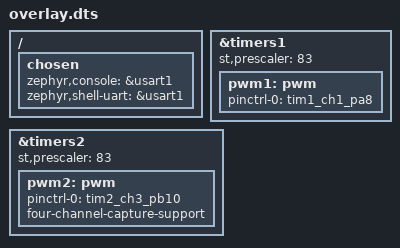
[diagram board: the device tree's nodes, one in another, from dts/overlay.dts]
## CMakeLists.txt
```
cmake_minimum_required(VERSION 3.20.0)

# ─── Point to our overlay before Zephyr loads ─────────────────────────────────
set(DTC_OVERLAY_FILE ${CMAKE_CURRENT_SOURCE_DIR}/dts/overlay.dts)

# ─── Zephyr package ───────────────────────────────────────────────────────────
find_package(Zephyr REQUIRED HINTS $ENV{ZEPHYR_BASE})
project(testbench)

# ─── Main executable ──────────────────────────────────────────────────────────
target_sources(app PRIVATE src/main.c)

# ─── Source library ───────────────────────────────────────────────────────────
target_sources(app PRIVATE
    src/serial_handler.c
    src/command_parser.c
    src/executor.c
    src/validator.c
    src/handlers/pwm_out.c
    src/handlers/pwm_capture.c
)

# ─── Include paths ────────────────────────────────────────────────────────────
target_include_directories(app PRIVATE
    src
    src/handlers
)
```

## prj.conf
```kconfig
# ─── UART ─────────────────────────────────────────────────────────────────────
CONFIG_SERIAL=y
CONFIG_UART_INTERRUPT_DRIVEN=y

# ─── PWM ──────────────────────────────────────────────────────────────────────
CONFIG_PWM=y
CONFIG_PWM_CAPTURE=y

# ─── Logging / debug ──────────────────────────────────────────────────────────
CONFIG_LOG=y
CONFIG_PRINTK=y
CONFIG_UART_CONSOLE=y

# ─── Main thread stack ────────────────────────────────────────────────────────
CONFIG_MAIN_STACK_SIZE=2048

# ─── Heap (needed for any dynamic allocation) ─────────────────────────────────
CONFIG_HEAP_MEM_POOL_SIZE=1024
```

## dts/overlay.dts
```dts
/*
 * Testbench overlay — STM32F401CC Black Pill
 *
 * PA8  — TIM1 CH1 — PWM output
 * PB10 — TIM2 CH3 — PWM capture
 * PA9  — USART1 TX (already in board file)
 * PA10 — USART1 RX (already in board file)
 */

#include <st/f4/stm32f401ccfx-pinctrl.dtsi>

/ {
    chosen {
        zephyr,console    = &usart1;
        zephyr,shell-uart = &usart1;
    };
};

/* ─── TIM1 — PWM output on PA8 (CH1) ────────────────────────────────────── */
&timers1 {
    status = "okay";
    st,prescaler = <83>;

    pwm1: pwm {
        status = "okay";
        pinctrl-0 = <&tim1_ch1_pa8>;
        pinctrl-names = "default";
        #pwm-cells = <3>;
    };
};

/* ─── TIM2 — PWM capture on PB10 (CH3) ──────────────────────────────────── */
&timers2 {
    status = "okay";
    st,prescaler = <83>;

    pwm2: pwm {
        status = "okay";
        pinctrl-0 = <&tim2_ch3_pb10>;
        pinctrl-names = "default";
        #pwm-cells = <3>;

        /* PB10 is TIM2_CH3. Default STM32 slave-mode capture only
         * works on CH1/CH2, so capturing on CH3 needs four-channel
         * mode (counter reset by IRQ instead of slave controller). */
        four-channel-capture-support;
    };
};
```

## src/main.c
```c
#include <zephyr/kernel.h>

#include "serial_handler.h"
#include "command_parser.h"
#include "executor.h"

#define RESP_BUF_SIZE   64
static char resp[RESP_BUF_SIZE];

/* ─────────────────────────────────────────────────────────────
 * main — all blocking work happens here in main loop
 * interrupt only sets a flag in serial_handler
 *
 * this is critical — pwm_capture_cycles blocks for timeout_ms
 * it CANNOT run inside an interrupt callback
 * ───────────────────────────────────────────────────────────── */
int main(void)
{
    /* static: parsed_cmd_t is ~2.5 KB — too large for the main stack
     * (CONFIG_MAIN_STACK_SIZE=2048). Single-threaded loop, so one
     * shared instance is safe and keeps it off the stack. */
    static parsed_cmd_t cmd;
    parse_result_t  pres;
    const char     *frame;

    /* init UART interrupt */
    serial_handler_init();

    while (1) {

        /* wait for a complete frame — sleep 1ms between checks */
        if (!serial_frame_ready()) {
            k_msleep(1);
            continue;
        }

        /* get the frame — clears the ready flag */
        frame = serial_get_frame();

        /* parse */
        pres = command_parse(frame, &cmd);
        if (pres != PARSE_OK) {
            serial_send(parse_result_str(pres));
            continue;
        }

        /* execute — blocking operations happen here safely */
        executor_run(&cmd, resp, RESP_BUF_SIZE);

        /* send response */
        serial_send(resp);
    }

    return 0;
}
```

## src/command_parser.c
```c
#include "command_parser.h"
#include <string.h>
#include <stdlib.h>

/* working buffer — we copy the frame here before splitting
 * because strtok destroys the string it works on            */
static char buf[256];

/* ─────────────────────────────────────────────────────────────
 * convert action string to enum
 * input : "PWM" / "GPIO" / "UART" / "SPI" / "ADC"
 * output: matching action_t value, or ACTION_UNKNOWN
 * ───────────────────────────────────────────────────────────── */
static action_t parse_action(const char *str)
{
    if (strcmp(str, "PWM")  == 0) return ACTION_PWM;
    if (strcmp(str, "GPIO") == 0) return ACTION_GPIO;
    if (strcmp(str, "UART") == 0) return ACTION_UART;
    if (strcmp(str, "SPI")  == 0) return ACTION_SPI;
    if (strcmp(str, "ADC")  == 0) return ACTION_ADC;

    return ACTION_UNKNOWN;
}

/* ─────────────────────────────────────────────────────────────
 * parse one operation from a colon-separated token
 *
 * example input : "PWM:PA8:50:90"
 * example output: op->action   = ACTION_PWM
 *                 op->pin      = "PA8"
 *                 op->num_params  = {50, 90}
 *                 op->num_param_count = 2
 *
 * rule: if param starts with digit  → goes to num_params
 *       if param starts with letter → goes to str_params
 * ───────────────────────────────────────────────────────────── */
static parse_result_t parse_operation(char *token, operation_t *op)
{
    char *field;
    char *save;     /* own strtok_r context — must not share with callers */

    /* zero the operation before filling it */
    memset(op, 0, sizeof(operation_t));

    /* ── step 1: action ── */
    field = strtok_r(token, ":", &save);
    if (!field) return PARSE_ERR_BAD_FRAME;

    op->action = parse_action(field);
    if (op->action == ACTION_UNKNOWN) return PARSE_ERR_BAD_ACTION;

    /* ── step 2: pin ── */
    field = strtok_r(NULL, ":", &save);
    if (!field) return PARSE_ERR_BAD_FRAME;

    strncpy(op->pin, field, MAX_PIN_LEN - 1);

    /* ── step 3: remaining params ── */
    field = strtok_r(NULL, ":", &save);

    while (field != NULL) {

        if (field[0] >= '0' && field[0] <= '9') {
            /* numeric param — e.g. "50", "90", "1" */
            op->num_params[op->num_param_count] = (uint32_t)atoi(field);
            op->num_param_count++;

        } else {
            /* string param — e.g. "forward", "0x55" */
            strncpy(op->str_params[op->str_param_count],
                    field,
                    MAX_STR_PARAM_LEN - 1);
            op->str_param_count++;
        }

        /* get next param */
        field = strtok_r(NULL, ":", &save);
    }

    return PARSE_OK;
}

/* ─────────────────────────────────────────────────────────────
 * parse a block of comma-separated operations
 *
 * example input : "GPIO:PB10:1,GPIO:PB9:1"
 * example output: ops[0] = {GPIO, PB10, num={1}}
 *                 ops[1] = {GPIO, PB9,  num={1}}
 *                 count  = 2
 * ───────────────────────────────────────────────────────────── */
static parse_result_t parse_block(char *block, operation_t *ops, uint8_t *count)
{
    parse_result_t res;
    char *token;
    char *save;     /* own strtok_r context — independent of parse_operation */

    *count = 0;

    /* split block by comma — each piece is one operation */
    token = strtok_r(block, ",", &save);

    while (token != NULL) {

        /* safety check — don't overflow ops array */
        if (*count >= MAX_OPS) return PARSE_ERR_TOO_MANY_OPS;

        /* parse this operation into the next slot */
        res = parse_operation(token, &ops[*count]);
        if (res != PARSE_OK) return res;

        (*count)++;

        /* move to next operation */
        token = strtok_r(NULL, ",", &save);
    }

    return PARSE_OK;
}

/* ─────────────────────────────────────────────────────────────
 * main parse function — only function called from outside
 *
 * full frame format:
 * "SET:<op>,<op>|ASSERT:<op>,<op>|TIMEOUT:<ms>"
 *
 * examples:
 * "SET:PWM:PA8:50:90|ASSERT:PWM:PB10:50:90|TIMEOUT:1000"
 * "SET:GPIO:PB10:1,GPIO:PB9:1|ASSERT:GPIO:PB11:1|TIMEOUT:500"
 * ───────────────────────────────────────────────────────────── */
parse_result_t command_parse(const char *frame, parsed_cmd_t *out)
{
    char *section;
    char *save;     /* own strtok_r context for the top-level '|' split */

    /* zero the output struct before filling it */
    memset(out, 0, sizeof(parsed_cmd_t));

    /* reject empty frame */
    if (!frame || frame[0] == '\0') return PARSE_ERR_EMPTY;

    /* copy frame into working buffer */
    strncpy(buf, frame, sizeof(buf) - 1);
    buf[sizeof(buf) - 1] = '\0';

    /* strip trailing newline */
    size_t len = strlen(buf);
    if (len > 0 && (buf[len-1] == '\n' || buf[len-1] == '\r')) {
        buf[len-1] = '\0';
    }

    /* split full frame by '|' to get sections
     * section 0 → "SET:..."
     * section 1 → "ASSERT:..."
     * section 2 → "TIMEOUT:..."         */
    section = strtok_r(buf, "|", &save);

    while (section != NULL) {

        if (strncmp(section, "SET:", 4) == 0) {
            /* skip past "SET:" and parse the operations block */
            parse_block(section + 4, out->set_ops, &out->set_count);

        } else if (strncmp(section, "ASSERT:", 7) == 0) {
            /* skip past "ASSERT:" and parse the operations block */
            parse_block(section + 7, out->assert_ops, &out->assert_count);

        } else if (strncmp(section, "TIMEOUT:", 8) == 0) {
            /* skip past "TIMEOUT:" and read the number */
            out->timeout_ms = (uint32_t)atoi(section + 8);

        } else {
            return PARSE_ERR_BAD_FRAME;
        }

        /* move to next section */
        section = strtok_r(NULL, "|", &save);
    }

    return PARSE_OK;
}

/* ─────────────────────────────────────────────────────────────
 * convert result code to string for UART response
 * ───────────────────────────────────────────────────────────── */
const char *parse_result_str(parse_result_t result)
{
    switch (result) {
        case PARSE_OK:               return "OK";
        case PARSE_ERR_EMPTY:        return "FAIL:EMPTY_FRAME";
        case PARSE_ERR_BAD_ACTION:   return "FAIL:BAD_ACTION";
        case PARSE_ERR_BAD_FRAME:    return "FAIL:BAD_FRAME";
        case PARSE_ERR_OUT_OF_RANGE: return "FAIL:OUT_OF_RANGE";
        case PARSE_ERR_TOO_MANY_OPS: return "FAIL:TOO_MANY_OPS";
        default:                     return "FAIL:UNKNOWN";
    }
}
```

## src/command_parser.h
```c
#ifndef COMMAND_PARSER_H
#define COMMAND_PARSER_H

#include <stdint.h>

/* ─── Limits ─────────────────────────────────────────────────────────────── */
#define MAX_PIN_LEN         8       /* "PA8", "PB10" etc                     */
#define MAX_STR_PARAMS      4       /* max string params per operation        */
#define MAX_STR_PARAM_LEN   32      /* max length of each string param        */
#define MAX_NUM_PARAMS      4       /* max numeric params per operation       */
#define MAX_OPS             8       /* max operations per SET or ASSERT block */

/* ─── Action types ───────────────────────────────────────────────────────── */
typedef enum {
    ACTION_UNKNOWN = 0,
    ACTION_PWM,
    ACTION_GPIO,
    ACTION_UART,
    ACTION_SPI,
    ACTION_ADC,
} action_t;

/* ─── Single operation ───────────────────────────────────────────────────── */
/*
 * One action on one pin with its parameters.
 *
 * How each action uses params:
 *
 *   PWM:
 *     num_params[0] = frequency (Hz)
 *     num_params[1] = duty cycle (%)
 *
 *   GPIO:
 *     num_params[0] = level (0 or 1)
 *
 *   UART:
 *     str_params[0] = string to send e.g. "forward"
 *     str_params[1] = string to expect (assert side)
 *
 *   SPI:
 *     str_params[0] = hex bytes to send e.g. "0x55"
 *     str_params[1] = hex bytes to expect (assert side)
 *
 *   ADC:
 *     num_params[0] = expected voltage in mV
 */
typedef struct {
    action_t    action;
    char        pin[MAX_PIN_LEN];

    uint32_t    num_params[MAX_NUM_PARAMS];
    uint8_t     num_param_count;

    char        str_params[MAX_STR_PARAMS][MAX_STR_PARAM_LEN];
    uint8_t     str_param_count;
} operation_t;

/* ─── Full parsed command ────────────────────────────────────────────────── */
/*
 * Holds all SET operations and all ASSERT operations from one frame.
 *
 * Example frame:
 * "SET:GPIO:PB10:1,GPIO:PB9:1,PWM:PA8:50:90|ASSERT:PWM:PB10:50:90,GPIO:PB11:1|TIMEOUT:1000"
 *
 * Results in:
 *   set_ops[0]    = {ACTION_GPIO, "PB10", num_params={1}}
 *   set_ops[1]    = {ACTION_GPIO, "PB9",  num_params={1}}
 *   set_ops[2]    = {ACTION_PWM,  "PA8",  num_params={50, 90}}
 *   set_count     = 3
 *
 *   assert_ops[0] = {ACTION_PWM,  "PB10", num_params={50, 90}}
 *   assert_ops[1] = {ACTION_GPIO, "PB11", num_params={1}}
 *   assert_count  = 2
 *
 *   timeout_ms    = 1000
 */
typedef struct {
    operation_t set_ops[MAX_OPS];
    uint8_t     set_count;

    operation_t assert_ops[MAX_OPS];
    uint8_t     assert_count;

    uint32_t    timeout_ms;
} parsed_cmd_t;

/* ─── Return codes ───────────────────────────────────────────────────────── */
typedef enum {
    PARSE_OK = 0,
    PARSE_ERR_EMPTY,
    PARSE_ERR_BAD_ACTION,
    PARSE_ERR_BAD_FRAME,
    PARSE_ERR_OUT_OF_RANGE,
    PARSE_ERR_TOO_MANY_OPS,
} parse_result_t;

/* ─── API ────────────────────────────────────────────────────────────────── */

/**
 * @brief  Parse a raw UART frame into a command struct.
 *
 * @param  frame      Null-terminated string received over UART.
 *
 *   Format:
 *   "SET:<op1>,<op2>,...|ASSERT:<op1>,<op2>,...|TIMEOUT:<ms>"
 *
 *   Each operation: <ACTION>:<PIN>:<param1>:<param2>...
 *
 *   Examples:
 *   "SET:PWM:PA8:50:90|ASSERT:PWM:PB10:50:90|TIMEOUT:1000"
 *   "SET:GPIO:PB10:1,GPIO:PB9:1|ASSERT:GPIO:PB11:1,GPIO:PB12:0|TIMEOUT:500"
 *   "SET:UART:PA9:forward|ASSERT:GPIO:PB11:1,GPIO:PB12:0|TIMEOUT:500"
 *   "SET:GPIO:PB10:1,GPIO:PB9:1,PWM:PA8:50:90|ASSERT:PWM:PB10:50:90|TIMEOUT:1000"
 *
 * @param  out        Pointer to struct to fill. Cleared before parsing.
 * @return parse_result_t
 */
parse_result_t command_parse(const char *frame, parsed_cmd_t *out);

/**
 * @brief  Convert a parse result code to a human readable string.
 */
const char *parse_result_str(parse_result_t result);

#endif /* COMMAND_PARSER_H */
```

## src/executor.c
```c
#include "executor.h"
#include "validator.h"
#include "handlers/pwm_out.h"
#include "handlers/pwm_capture.h"

#include <zephyr/kernel.h>
#include <string.h>

/* settle time after SET before measuring — fixed 50ms */
#define SETTLE_MS   50

/* ─────────────────────────────────────────────────────────────
 * execute one SET operation
 * ───────────────────────────────────────────────────────────── */
static int execute_set(const operation_t *op, char *resp, uint16_t resp_len)
{
    switch (op->action) {

        case ACTION_PWM: {
            /* num_params[0] = frequency (Hz)
             * num_params[1] = duty cycle (%)  */
            pwm_out_result_t res = pwm_out_start(op->pin,
                                                  op->num_params[0],
                                                  op->num_params[1]);
            if (res != PWM_OUT_OK) {
                strncpy(resp, pwm_out_result_str(res), resp_len - 1);
                return -1;
            }
            return 0;
        }

        default:
            strncpy(resp, "FAIL:UNKNOWN_SET_ACTION", resp_len - 1);
            return -1;
    }
}

/* ─────────────────────────────────────────────────────────────
 * execute one ASSERT operation
 * ───────────────────────────────────────────────────────────── */
static int execute_assert(const operation_t *op,
                          uint32_t timeout_ms,
                          char *resp,
                          uint16_t resp_len)
{
    measured_t measured;
    validate_result_t vres;

    switch (op->action) {

        case ACTION_PWM: {
            /* measure PWM on the assert pin */
            pwm_cap_result_t res = pwm_capture_measure(op->pin,
                                                        timeout_ms,
                                                        &measured);
            /* capture failed — timeout or device error */
            if (res != PWM_CAP_OK) {
                strncpy(resp, pwm_cap_result_str(res), resp_len - 1);
                return -1;
            }

            /* validate measured vs expected */
            vres = validate(op, &measured);
            if (vres != VALIDATE_OK) {
                strncpy(resp, validate_result_str(vres), resp_len - 1);
                return -1;
            }

            return 0;
        }

        default:
            strncpy(resp, "FAIL:UNKNOWN_ASSERT_ACTION", resp_len - 1);
            return -1;
    }
}

/* ─────────────────────────────────────────────────────────────
 * main executor
 *
 * phase 1 — SET:    drive all set operations
 * phase 2 — WAIT:   fixed settle time (50ms)
 * phase 3 — ASSERT: measure and validate all assert operations
 *           uses timeout_ms from command as capture window
 * ───────────────────────────────────────────────────────────── */
void executor_run(const parsed_cmd_t *cmd, char *resp, uint16_t resp_len)
{
    memset(resp, 0, resp_len);

    /* ── phase 1: SET ── */
    for (uint8_t i = 0; i < cmd->set_count; i++) {
        if (execute_set(&cmd->set_ops[i], resp, resp_len) != 0) {
            return;
        }
    }

    /* ── phase 2: WAIT ──
     * fixed settle time — gives signal time to stabilise
     * separate from capture timeout                          */
    k_msleep(SETTLE_MS);

    /* ── phase 3: ASSERT ── */
    for (uint8_t i = 0; i < cmd->assert_count; i++) {
        if (execute_assert(&cmd->assert_ops[i],
                           cmd->timeout_ms,
                           resp,
                           resp_len) != 0) {
            return;
        }
    }

    strncpy(resp, "OK", resp_len - 1);
}
```

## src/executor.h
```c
#ifndef EXECUTOR_H
#define EXECUTOR_H

#include "command_parser.h"

/* ─── Return codes ───────────────────────────────────────────────────────── */
typedef enum {
    EXEC_OK = 0,
    EXEC_FAIL_SET,              /* something went wrong during SET phase      */
    EXEC_FAIL_ASSERT,           /* assertion failed — measured != expected    */
    EXEC_FAIL_UNKNOWN_ACTION,   /* action type not supported                  */
    EXEC_FAIL_CAPTURE,          /* capture/measurement failed                 */
} exec_result_t;

/* ─── API ────────────────────────────────────────────────────────────────── */

/**
 * @brief  Execute a fully parsed command.
 *
 *         Phase 1 — SET:    loop through set_ops, drive each one
 *         Phase 2 — WAIT:   wait timeout_ms for DUT to settle
 *         Phase 3 — ASSERT: loop through assert_ops, measure and validate each
 *
 * @param  cmd        Fully parsed command from command_parse()
 * @param  resp       Buffer to write the response string into
 * @param  resp_len   Size of response buffer
 */
void executor_run(const parsed_cmd_t *cmd, char *resp, uint16_t resp_len);

#endif /* EXECUTOR_H */
```

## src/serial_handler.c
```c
#include "serial_handler.h"

#include <zephyr/kernel.h>
#include <zephyr/drivers/uart.h>
#include <string.h>

static const struct device *uart = DEVICE_DT_GET(DT_CHOSEN(zephyr_console));

static char     rx_buf[SERIAL_BUF_SIZE];    /* accumulate bytes here        */
static char     frame_buf[SERIAL_BUF_SIZE]; /* complete frame stored here   */
static uint16_t rx_pos   = 0;
static bool     frame_ready = false;        /* set by ISR, cleared by main  */

/* ─────────────────────────────────────────────────────────────
 * UART interrupt — runs in interrupt context
 * ONLY accumulates bytes and sets a flag
 * does NOT call any blocking functions
 * ───────────────────────────────────────────────────────────── */
static void uart_cb(const struct device *dev, void *user_data)
{
    uint8_t byte;

    if (!uart_irq_update(dev) || !uart_irq_rx_ready(dev)) {
        return;
    }

    while (uart_fifo_read(dev, &byte, 1) == 1) {

        if (byte == '\r') continue;

        if (byte == '\n') {
            rx_buf[rx_pos] = '\0';

            /* only accept frame if we are not already processing one */
            if (rx_pos > 0 && !frame_ready) {
                memcpy(frame_buf, rx_buf, rx_pos + 1);
                frame_ready = true;
            }

            rx_pos = 0;
            return;
        }

        if (rx_pos < SERIAL_BUF_SIZE - 1) {
            rx_buf[rx_pos++] = byte;
        } else {
            rx_pos = 0;
        }
    }
}

void serial_handler_init(void)
{
    if (!device_is_ready(uart)) return;
    uart_irq_callback_set(uart, uart_cb);
    uart_irq_rx_enable(uart);
}

/* ─────────────────────────────────────────────────────────────
 * poll from main loop — safe to call anytime
 * ───────────────────────────────────────────────────────────── */
bool serial_frame_ready(void)
{
    return frame_ready;
}

const char *serial_get_frame(void)
{
    frame_ready = false;    /* clear flag — ready for next frame */
    return frame_buf;
}

void serial_send(const char *msg)
{
    while (*msg != '\0') {
        uart_poll_out(uart, *msg++);
    }
    uart_poll_out(uart, '\n');
}
```

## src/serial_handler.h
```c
#ifndef SERIAL_HANDLER_H
#define SERIAL_HANDLER_H

#include <stdint.h>
#include <stdbool.h>

#define SERIAL_BUF_SIZE     256

/* ─────────────────────────────────────────────────────────────
 * init UART interrupt — call once from main
 * ───────────────────────────────────────────────────────────── */
void serial_handler_init(void);

/* ─────────────────────────────────────────────────────────────
 * check if a complete frame has arrived
 * call from main loop — NOT from interrupt context
 * ───────────────────────────────────────────────────────────── */
bool serial_frame_ready(void);

/* ─────────────────────────────────────────────────────────────
 * get the received frame — call after serial_frame_ready()
 * clears the ready flag so next frame can be received
 * ───────────────────────────────────────────────────────────── */
const char *serial_get_frame(void);

/* ─────────────────────────────────────────────────────────────
 * send a string over UART
 * ───────────────────────────────────────────────────────────── */
void serial_send(const char *msg);

#endif /* SERIAL_HANDLER_H */
```

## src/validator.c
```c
#include "validator.h"
#include <string.h>

/* ─── PWM tolerances ──────────────────────────────────────────
 * Four-channel capture resets the counter in the ISR rather than
 * the slave-mode controller, so the measured period can jitter by
 * a few timer cycles. With exact == that flips integer-divided
 * results (e.g. 1000000/20001 = 49 instead of 50), so we allow a
 * small band instead.
 *
 *   FREQ_TOL_PCT : allowed frequency error, percent of expected
 *   DUTY_TOL_PP  : allowed duty error, absolute percentage points
 * ───────────────────────────────────────────────────────────── */
#define FREQ_TOL_PCT    2u
#define DUTY_TOL_PP     2u

/* absolute difference for unsigned values (no underflow) */
static uint32_t udiff(uint32_t a, uint32_t b)
{
    return (a > b) ? (a - b) : (b - a);
}

/* ─────────────────────────────────────────────────────────────
 * main validate function
 *
 * looks at expected->action to know what to compare
 * then compares expected params against measured values
 * ───────────────────────────────────────────────────────────── */
validate_result_t validate(const operation_t *expected, const measured_t *measured)
{
    switch (expected->action) {

        /* ── PWM ──────────────────────────────────────────────
         * num_params[0] = expected frequency (Hz)
         * num_params[1] = expected duty cycle (%)
         * ───────────────────────────────────────────────────── */
        case ACTION_PWM:

            /* check frequency — within FREQ_TOL_PCT % of expected */
            if (udiff(measured->num_values[0], expected->num_params[0]) * 100u
                    > expected->num_params[0] * FREQ_TOL_PCT) {
                return VALIDATE_FAIL_FREQ;
            }

            /* check duty cycle — within DUTY_TOL_PP percentage points */
            if (udiff(measured->num_values[1], expected->num_params[1])
                    > DUTY_TOL_PP) {
                return VALIDATE_FAIL_DUTY;
            }

            return VALIDATE_OK;

        /* ── GPIO ─────────────────────────────────────────────
         * num_params[0] = expected level (0 or 1)
         * ───────────────────────────────────────────────────── */
        case ACTION_GPIO:

            if (measured->num_values[0] != expected->num_params[0]) {
                return VALIDATE_FAIL_GPIO;
            }

            return VALIDATE_OK;

        /* ── UART ─────────────────────────────────────────────
         * str_params[0] = expected string response
         * ───────────────────────────────────────────────────── */
        case ACTION_UART:

            if (strcmp(measured->str_values[0], expected->str_params[0]) != 0) {
                return VALIDATE_FAIL_UART;
            }

            return VALIDATE_OK;

        /* ── SPI ──────────────────────────────────────────────
         * str_params[0] = expected bytes e.g. "0x55"
         * ───────────────────────────────────────────────────── */
        case ACTION_SPI:

            if (strcmp(measured->str_values[0], expected->str_params[0]) != 0) {
                return VALIDATE_FAIL_SPI;
            }

            return VALIDATE_OK;

        /* ── ADC ──────────────────────────────────────────────
         * num_params[0] = expected voltage in mV
         * ───────────────────────────────────────────────────── */
        case ACTION_ADC:

            if (measured->num_values[0] != expected->num_params[0]) {
                return VALIDATE_FAIL_ADC;
            }

            return VALIDATE_OK;

        default:
            return VALIDATE_FAIL_UNKNOWN;
    }
}

/* ─────────────────────────────────────────────────────────────
 * convert result to string for UART response
 * ───────────────────────────────────────────────────────────── */
const char *validate_result_str(validate_result_t result)
{
    switch (result) {
        case VALIDATE_OK:           return "OK";
        case VALIDATE_FAIL_FREQ:    return "FAIL:FREQ_MISMATCH";
        case VALIDATE_FAIL_DUTY:    return "FAIL:DUTY_MISMATCH";
        case VALIDATE_FAIL_GPIO:    return "FAIL:GPIO_MISMATCH";
        case VALIDATE_FAIL_UART:    return "FAIL:UART_MISMATCH";
        case VALIDATE_FAIL_SPI:     return "FAIL:SPI_MISMATCH";
        case VALIDATE_FAIL_ADC:     return "FAIL:ADC_MISMATCH";
        case VALIDATE_FAIL_TIMEOUT: return "FAIL:TIMEOUT";
        case VALIDATE_FAIL_UNKNOWN: return "FAIL:UNKNOWN_ACTION";
        default:                    return "FAIL:UNKNOWN";
    }
}
```

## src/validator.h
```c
#ifndef VALIDATOR_H
#define VALIDATOR_H

#include <stdint.h>
#include "command_parser.h"

/* ─── Validation result ──────────────────────────────────────────────────── */
typedef enum {
    VALIDATE_OK = 0,
    VALIDATE_FAIL_FREQ,         /* measured frequency does not match expected */
    VALIDATE_FAIL_DUTY,         /* measured duty cycle does not match expected */
    VALIDATE_FAIL_GPIO,         /* pin level does not match expected           */
    VALIDATE_FAIL_UART,         /* uart response does not match expected       */
    VALIDATE_FAIL_SPI,          /* spi response does not match expected        */
    VALIDATE_FAIL_ADC,          /* adc voltage does not match expected         */
    VALIDATE_FAIL_TIMEOUT,      /* measurement timed out                       */
    VALIDATE_FAIL_UNKNOWN,      /* action not supported                        */
} validate_result_t;

/* ─── Measured values struct ─────────────────────────────────────────────── */
/*
 * Filled by the handler (pwm_capture, gpio_handler etc.)
 * then passed to validate() alongside the expected operation_t
 */
typedef struct {
    uint32_t    num_values[MAX_NUM_PARAMS];     /* measured numeric values   */
    uint8_t     num_value_count;

    char        str_values[MAX_STR_PARAMS][MAX_STR_PARAM_LEN]; /* measured strings */
    uint8_t     str_value_count;
} measured_t;

/* ─── API ────────────────────────────────────────────────────────────────── */

/**
 * @brief  Compare measured values against one expected operation.
 *
 * @param  expected   The assert operation from parsed_cmd_t.
 * @param  measured   Values read back from hardware.
 * @return validate_result_t
 */
validate_result_t validate(const operation_t *expected, const measured_t *measured);

/**
 * @brief  Convert validation result to response string for UART.
 */
const char *validate_result_str(validate_result_t result);

#endif /* VALIDATOR_H */
```
